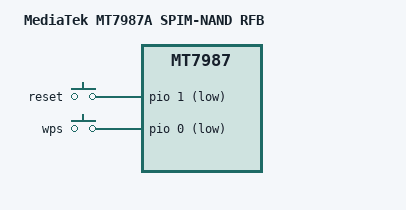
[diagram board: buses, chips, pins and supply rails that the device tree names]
// SPDX-License-Identifier: (GPL-2.0 OR MIT)

/dts-v1/;
#include "mt7987a.dtsi"
#include "mt7987-spim-nand.dtsi"
#include "mt7987a-spim-nand-rfb-u-boot.dtsi"
#include <dt-bindings/input/input.h>

/ {
	model = "MediaTek MT7987A SPIM-NAND RFB";
	compatible = "mediatek,mt7987a-spim-snand",
		     "mediatek,mt7987a", "mediatek,mt7987";

	chosen {
		bootargs = "console=ttyS0,115200n1 loglevel=8";
	};

	gpio-keys {
		compatible = "gpio-keys";

		reset {
			label = "reset";
			linux,code = <KEY_RESTART>;
			gpios = <&pio 1 GPIO_ACTIVE_LOW>;
			debounce-interval = <10>;
		};

		wps {
			label = "wps";
			linux,code = <KEY_WPS_BUTTON>;
			gpios = <&pio 0 GPIO_ACTIVE_LOW>;
			debounce-interval = <10>;
		};
	};
};
